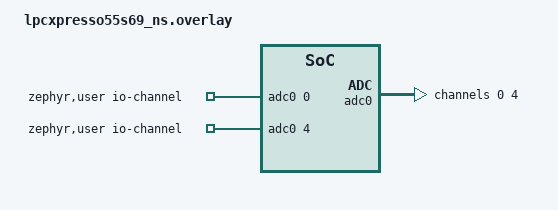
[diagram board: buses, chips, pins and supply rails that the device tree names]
/*
 * SPDX-License-Identifier: Apache-2.0
 *
 * Copyright (c) 2023 Benjamin Björnsson <benjamin.bjornsson@gmail.com>
 */

#include <zephyr/dt-bindings/adc/adc.h>
#include <zephyr/dt-bindings/adc/mcux-lpadc.h>

/ {
	zephyr,user {
		io-channels = <&adc0 0>, <&adc0 4>;
	};
};

&adc0 {
	#address-cells = <1>;
	#size-cells = <0>;

	channel@0 {
		reg = <0>;
		zephyr,gain = "ADC_GAIN_1";
		zephyr,reference = "ADC_REF_EXTERNAL0";
		zephyr,acquisition-time = <ADC_ACQ_TIME_DEFAULT>;
		zephyr,resolution = <12>;
                zephyr,input-positive = <MCUX_LPADC_CH0A>;
	};

	channel@4 {
		reg = <4>;
		zephyr,gain = "ADC_GAIN_1";
		zephyr,reference = "ADC_REF_EXTERNAL0";
		zephyr,acquisition-time = <ADC_ACQ_TIME_DEFAULT>;
		zephyr,resolution = <12>;
                zephyr,input-positive = <MCUX_LPADC_CH1A>;
	};
};
